# STM32WBA24 register map
File version: 0.2
CPU: CM33 r0p1, little endian, MPU, FPU, 4 interrupt priority bits
Registers are 32-bit, read-write, reset 0x0 unless marked. A register's access mark holds for its fields unless they carry their own. Offsets are from the block's base; [hi:lo] are bit positions; {n}, {i} and the like mark numbered series.

## PKA — PKA register blank and RAM
Base 0x420C2000
Same registers: SEC_PKA 0x520C2000
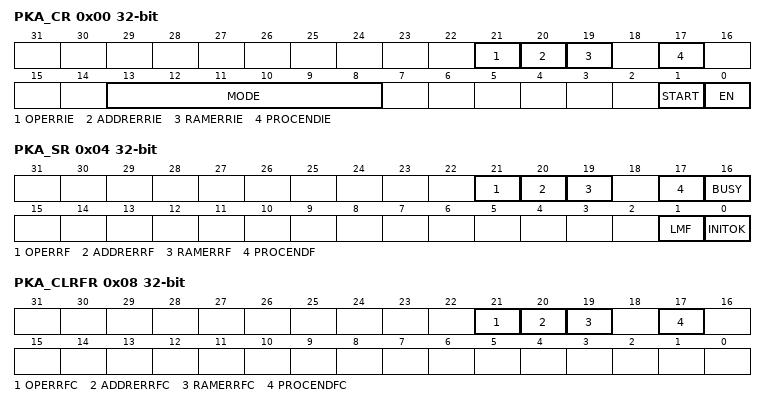
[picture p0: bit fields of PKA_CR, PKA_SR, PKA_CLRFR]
0x00 PKA_CR — PKA control register
  [21] OPERRIE — Operation error interrupt enable
    0=No interrupt is generated when OPERRF flag is set in PKA_SR; 1=An interrupt is generated when OPERRF flag is set in PKA_SR
  [20] ADDRERRIE — Address error interrupt enable
    0=No interrupt is generated when ADDRERRF flag is set in PKA_SR; 1=An interrupt is generated when ADDRERRF flag is set in PKA_SR
  [19] RAMERRIE — RAM error interrupt enable
    0=No interrupt is generated when RAMERRF flag is set in PKA_SR; 1=An interrupt is generated when RAMERRF flag is set in PKA_SR
  [17] PROCENDIE — End of operation interrupt enable
    0=No interrupt is generated when PROCENDF flag is set in PKA_SR; 1=An interrupt is generated when PROCENDF flag is set in PKA_SR
  [13:8] MODE — PKA operation code
    0=Montgomery parameter computation then modular exponentiation; 1=Montgomery parameter computation only; 2=Modular exponentiation only (Montgomery parameter must be loaded first); 3=Modular exponentiation (protected, used when manipulating secrets); 32=Montgomery parameter computation then ECC scalar multiplication; 36=ECDSA sign; 38=ECDSA verification; 40=Point on elliptic curve Fp check; 7=RSA CRT exponentiation; 8=Modular inversion; 9=Arithmetic addition; 10=Arithmetic subtraction; 11=Arithmetic multiplication; 12=Arithmetic comparison; 13=Modular reduction; 14=Modular addition; 15=Modular subtraction; 16=Montgomery multiplication; 35=ECC complete addition; 39=ECC double base ladder; 47=ECC projective to affine
  [1] START — start the operation
  [0] EN — PKA enable
    0=Disable PKA; 1=Enable PKA
0x04 PKA_SR ro — PKA status register
  [21] OPERRF — Operation error flag
    0=No event error; 1=An illegal or unknown operation has been selected in PKA_CR register
  [20] ADDRERRF — Address error flag
    0=No address error; 1=Address access is out of range (unmapped address)
  [19] RAMERRF — PKA RAM error flag
    0=No PKA RAM access error; 1=An AHB access to the PKA RAM occurred while the PKA core was computing and using its internal RAM (AHB PKA_RAM access are not allowed while PKA operation is in progress)
  [17] PROCENDF — PKA end of operation flag
    0=Operation in progress; 1=PKA operation is completed
  [16] BUSY — Busy flag
    0=No operation is in progress (default); 1=An operation is in progress
  [1] LMF — Limited mode flag
    0=All values documented in MODE bit field can be used; 1=Only ECDSA verification (MODE = 0x26) is supported by the PKA
  [0] INITOK — PKA initialization OK
    0=PKA is not initialized correctly; 1=PKA is initialized correctly and can be used normally
0x08 PKA_CLRFR wo — PKA clear flag register
  [21] OPERRFC — Clear operation error flag
    0=No action; 1=Clear the OPERRF flag in PKA_SR
  [20] ADDRERRFC — Clear address error flag
    0=No action; 1=Clear the ADDRERRF flag in PKA_SR
  [19] RAMERRFC — Clear PKA RAM error flag
    0=No action; 1=Clear the RAMERRF flag in PKA_SR
  [17] PROCENDFC — Clear PKA end of operation flag
    0=No action; 1=Clear the PROCENDF flag in PKA_SR

## RAMCFG — RAMCFG address block description
Base 0x40026000
Same registers: SEC_RAMCFG 0x50026000
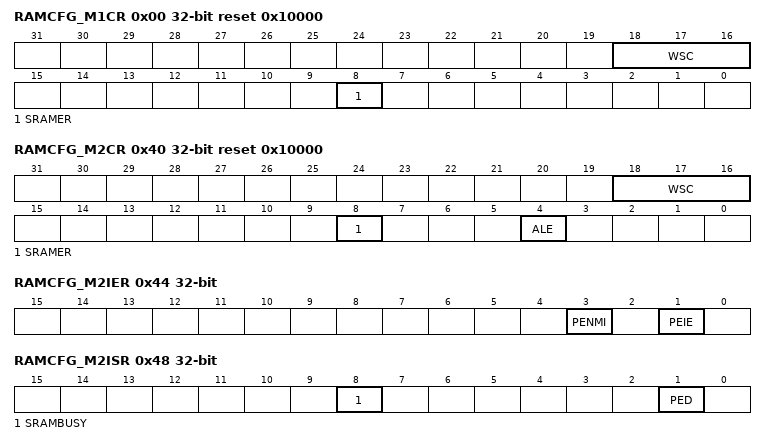
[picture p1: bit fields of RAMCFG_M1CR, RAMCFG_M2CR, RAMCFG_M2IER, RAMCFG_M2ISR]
0x00 RAMCFG_M1CR reset 0x10000 — RAMCFG SRAM1 control register
  [18:16] WSC — SRAM1 wait state configuration
    0=Zero wait states; 1=One wait state; 7=Seven wait states
  [8] SRAMER — SRAM1 erase
    0=No erase operation ongoing; 1=Erase operation ongoing
0x08 RAMCFG_M1ISR ro — RAMCFG SRAM1 interrupt status register
  [8] SRAMBUSY — SRAM busy with erase operation.
    0=No memory erase operation ongoing; 1=Memory erase operation ongoing
0x28 RAMCFG_M1ERKEYR wo — RAMCFG SRAM erase key register
  [7:0] ERASEKEY — Erase write protection key
0x40 RAMCFG_M2CR reset 0x10000 — RAMCFG SRAM2 control register
  [18:16] WSC — SRAM2 wait state configuration
    0=0 wait state; 1=1 wait state; 7=7 wait states
  [8] SRAMER — SRAM2 erase
    0=No erase operation on going; 1=Erase operation on going
  [4] ALE — SRAM2 parity fail address latch enable
    0=Failing address not stored in the SRAM2 parity error address register RAMCFG_M2PEAR; 1=Failing address stored in the SRAM2 parity error address register RAMCFG_M2PEAR
0x44 RAMCFG_M2IER — RAMCFG SRAM2 interrupt enable register
  [3] PENMI — Parity error NMI.
    0=NMI not generated in case of parity error; 1=NMI generated in case of parity error
  [1] PEIE — Parity error interrupt enable
    0=parity error interrupt disabled; 1=party error interrupt enabled
0x48 RAMCFG_M2ISR ro — RAMCFG SRAM2 interrupt status register
  [8] SRAMBUSY — SRAM2 busy with erase operation.
    0=no memory erase operation ongoing; 1=memory erase operation ongoing
  [1] PED — Parity error detected
    0=no parity error detected; 1=parity error detected
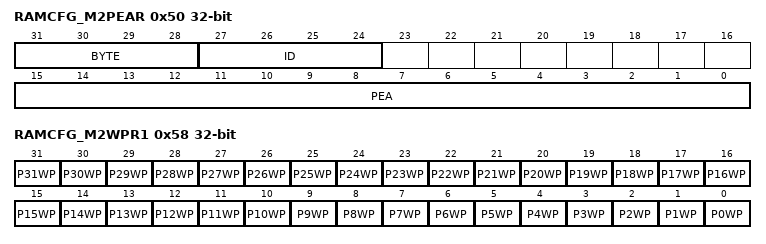
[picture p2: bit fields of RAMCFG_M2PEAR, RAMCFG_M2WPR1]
0x50 RAMCFG_M2PEAR ro — RAMCFG SRAM2 parity error address register
  [31:28] BYTE — Byte parity error flag.
  [27:24] ID — Parity error AHB bus master ID.
    2=parity error detected on CPU access; 3=parity error detected on Debugger access; 6=parity error detected on DMA master port o access; 7=parity error detected on DMA master port 1 access
  [15:0] PEA — Parity error SRAM word aligned address offset.
0x54 RAMCFG_M2ICR — RAMCFG SRAM2 interrupt clear register
  [1] CPED — Clear parity error detect bit
0x58 RAMCFG_M2WPR1 — RAMCFG SRAM2 write protection register 1
  [all] fields
    0=Write protection of SRAM2 1-Kbyte write protect page y is disabled; 1=Write protection of SRAM2 1-Kbyte write protect page y is enabled
  [n] P{n}WP (n=0..31) — SRAM2 1-Kbyte write protect page y write protection
0x68 RAMCFG_M2ERKEYR wo — RAMCFG SRAM erase key register
  [7:0] ERASEKEY — Erase write protection key

## RNG — RNG address block description
Base 0x420C0800
Same registers: SEC_RNG 0x520C0800
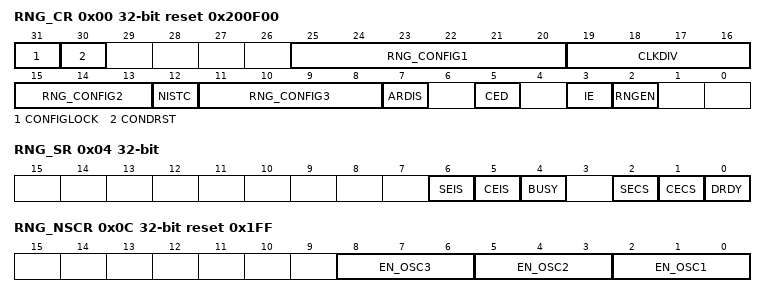
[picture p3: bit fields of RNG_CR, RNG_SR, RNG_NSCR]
0x00 RNG_CR reset 0x200F00 — RNG control register
  [31] CONFIGLOCK — RNG Config lock
    0=Writes to the RNG_NSCR, RNG_HTCR and the RNG_CR configuration bits [29:4] are allowed; 1=Writes to the RNG_NSCR, RNG_HTCR and the RNG_CR configuration bits [29:4] are ignored until the next RNG reset
  [30] CONDRST — Conditioning soft reset
  [25:20] RNG_CONFIG1 — RNG configuration 1
  [19:16] CLKDIV — Clock divider factor
    0=internal RNG clock after divider is similar to incoming RNG clock; 1=two RNG clock cycles per internal RNG clock; 2=2<sup>2</sup> (= 4) RNG clock cycles per internal RNG clock; 15=2<sup>15</sup> RNG clock cycles per internal clock (for example
  [15:13] RNG_CONFIG2 — RNG configuration 2
  [12] NISTC — NIST custom
    0=Hardware default values for NIST compliant RNG; 1=Custom values for NIST compliant RNG
  [11:8] RNG_CONFIG3 — RNG configuration 3
  [7] ARDIS — Auto reset disable
    0=Auto-reset is enabled; 1=Auto-reset is disabled
  [5] CED — Clock error detection
    0=Clock error detection is enabled; 1=Clock error detection is disabled
  [3] IE — Interrupt enable
    0=RNG interrupt is disabled; 1=RNG interrupt is enabled
  [2] RNGEN — True random number generator enable
    0=True random number generator disabled; 1=True random number generator enabled
0x04 RNG_SR — RNG status register
  [6] SEIS — Seed error interrupt status
    0=No faulty sequence detected; 1=At least one faulty sequence is detected
  [5] CEIS — Clock error interrupt status
    0=The RNG clock is correct (f<sub>RNGCLK</sub>> f<sub>HCLK</sub>/32); 1=The RNG clock before the internal divider is detected too slow (f<sub>RNGCLK</sub>< f<sub>HCLK</sub>/32)
  [4] BUSY ro
    0=Idle; 1=Busy
  [2] SECS ro — Seed error current status
    0=No faulty sequence has currently been detected; 1=At least one of the following faulty sequence has been detected:
  [1] CECS ro — Clock error current status
    0=The RNG clock is correct (f<sub>RNGCLK</sub>> f<sub>HCLK</sub>/32); 1=The RNG clock is too slow (f<sub>RNGCLK</sub>< f<sub>HCLK</sub>/32)
  [0] DRDY ro — Data ready
    0=No valid random data ready; 1=Valid random data ready
0x08 RNG_DR ro — RNG data register
  [31:0] RNDATA — Random data
0x0C RNG_NSCR reset 0x1FF — RNG noise source control register
  [8:6] EN_OSC3 — Each bit drives one oscillator enable signal input of instance number 3, gated with the RNGEN bit in RNG_CR (set bit to enable the oscillator).
  [5:3] EN_OSC2 — Each bit drives one oscillator enable signal input of instance number 2, gated with the RNGEN bit in RNG_CR (set bit to enable the oscillator).
  [2:0] EN_OSC1 — Each bit drives one oscillator enable signal input of instance number 1, gated with the RNGEN bit in RNG_CR (set bit to enable the oscillator).
0x10 RNG_HTCR0 reset 0x72AC — RNG health test control register 0
  [31:0] HTCFG — health test configuration
{0x10+4i} RNG_HTCR{i} reset 0xFFFF (i=1..3) — RNG health test control register {i}
  [31:0] HTCFG — health test configuration
